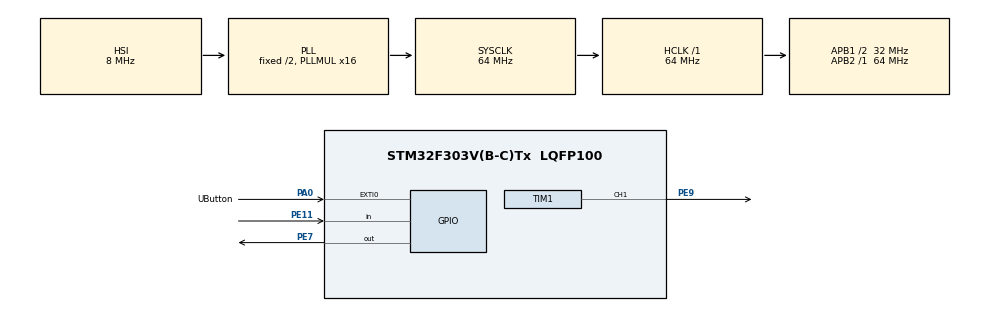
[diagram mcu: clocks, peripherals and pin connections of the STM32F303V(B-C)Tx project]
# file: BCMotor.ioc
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Mcu.Family=STM32F3
Mcu.Name=STM32F303V(B-C)Tx
Mcu.Package=LQFP100
NVIC.EXTI0_IRQn=true\:0\:0\:false\:false\:true\:true\:true
NVIC.PriorityGroup=NVIC_PRIORITYGROUP_0
NVIC.TIM1_CC_IRQn=true\:0\:0\:false\:false\:true\:true\:true
PA0.GPIO_Label=UButton
PA0.Signal=GPXTI0
PE11.Signal=GPIO_Input
PE7.Signal=GPIO_Output
PE9.Signal=S_TIM1_CH1
PF0-OSC_IN.GPIO_Label=OSC_IN
PF0-OSC_IN.Mode=HSE-External-Oscillator
PF0-OSC_IN.Signal=RCC_OSC_IN
PF1-OSC_OUT.Mode=HSE-External-Oscillator
PF1-OSC_OUT.Signal=RCC_OSC_OUT
ProjectManager.HeapSize=0x200
ProjectManager.StackSize=0x400
ProjectManager.TargetToolchain=SW4STM32
RCC.AHBFreq_Value=64000000
RCC.APB1CLKDivider=RCC_HCLK_DIV2
RCC.APB1Freq_Value=32000000
RCC.APB1TimFreq_Value=64000000
RCC.APB2Freq_Value=64000000
RCC.APB2TimFreq_Value=64000000
RCC.CortexFreq_Value=64000000
RCC.HCLKFreq_Value=64000000
RCC.HSE_VALUE=8000000
RCC.HSI_VALUE=8000000
RCC.LSE_VALUE=32768
RCC.PLLMUL=RCC_PLL_MUL16
RCC.SYSCLKFreq_VALUE=64000000
RCC.SYSCLKSourceVirtual=RCC_SYSCLKSOURCE_PLLCLK
RCC.USBFreq_Value=64000000
SH.S_TIM1_CH1.0=TIM1_CH1,PWM Generation1 CH1
TIM1.Channel-PWM\ Generation1\ CH1=TIM_CHANNEL_1
TIM1.Period=100
TIM1.Prescaler=64
TIM1.Pulse-PWM\ Generation1\ CH1=50
VP_TIM1_VS_ClockSourceINT.Mode=Internal
board=STM32F3DISCOVERY

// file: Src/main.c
/* USER CODE BEGIN Header */
/**
  ******************************************************************************
  * @file           : main.c
  * @brief          : Main program body
  ******************************************************************************
  * @attention
  *
  * <h2><center>&copy; Copyright (c) 2019 STMicroelectronics.
  * All rights reserved.</center></h2>
  *
  * This software component is licensed by ST under BSD 3-Clause license,
  * the "License"; You may not use this file except in compliance with the
  * License. You may obtain a copy of the License at:
  *                        opensource.org/licenses/BSD-3-Clause
  *
  ******************************************************************************
  */
/* USER CODE END Header */

#include "main.h"
#include "tim.h"
#include "gpio.h"

void SystemClock_Config(void);
/* USER CODE BEGIN PFP */
volatile int button_is_pressed = 1;
void HAL_GPIO_EXTI_Callback(uint16_t GPIO_Pin)
{
 if( GPIO_Pin == UButton_Pin)
 {
  static uint32_t last_change_tick;
  if( HAL_GetTick() - last_change_tick < 50 )
  {
   return;
  }
  last_change_tick = HAL_GetTick();
  if(button_is_pressed)
  {
   button_is_pressed = 0;
  }else
  {
   button_is_pressed = 1;
  }
 }
}
/* USER CODE END PFP */

int main(void)
{

  /* MCU Configuration--------------------------------------------------------*/

  /* Reset of all peripherals, Initializes the Flash interface and the Systick. */
  HAL_Init();

  /* Configure the system clock */
  SystemClock_Config();

  /* Initialize all configured peripherals */
  MX_GPIO_Init();
  MX_TIM1_Init();
  /* USER CODE BEGIN 2 */
//  HAL_TIM_PWM_Start(&htim1, TIM_CHANNEL_1);
  /* USER CODE END 2 */

  /* Infinite loop */
  /* USER CODE BEGIN WHILE */
  while (1)
  {
//	  __enable_irq();
//	  if(button_is_pressed) {
//		  HAL_GPIO_WritePin(GPIOE, GPIO_PIN_7, GPIO_PIN_SET);
//		  TIM1->CCR1 = 300;
//	  } else {
//		  HAL_GPIO_WritePin(GPIOE, GPIO_PIN_7, GPIO_PIN_RESET);
//		  TIM1->CCR1 = 750;
//	  }
//
//	  __disable_irq();
	  HAL_GPIO_WritePin(GPIOE, GPIO_PIN_7, GPIO_PIN_SET);
//	  HAL_GPIO_WritePin(GPIOE, GPIO_PIN_9, GPIO_PIN_SET);
	  HAL_GPIO_WritePin(GPIOE, GPIO_PIN_11, GPIO_PIN_RESET);
//	     HAL_Delay(100);
//	     HAL_GPIO_WritePin(GPIOE, GPIO_PIN_8, GPIO_PIN_RESET);
//	     HAL_Delay(100);

    /* USER CODE END WHILE */

  }
}

void SystemClock_Config(void)
{
  RCC_OscInitTypeDef RCC_OscInitStruct = {0};
  RCC_ClkInitTypeDef RCC_ClkInitStruct = {0};
  RCC_PeriphCLKInitTypeDef PeriphClkInit = {0};

  /** Initializes the CPU, AHB and APB busses clocks
  */
  RCC_OscInitStruct.OscillatorType = RCC_OSCILLATORTYPE_HSI;
  RCC_OscInitStruct.HSIState = RCC_HSI_ON;
  RCC_OscInitStruct.HSICalibrationValue = RCC_HSICALIBRATION_DEFAULT;
  RCC_OscInitStruct.PLL.PLLState = RCC_PLL_ON;
  RCC_OscInitStruct.PLL.PLLSource = RCC_PLLSOURCE_HSI;
  RCC_OscInitStruct.PLL.PLLMUL = RCC_PLL_MUL16;
  if (HAL_RCC_OscConfig(&RCC_OscInitStruct) != HAL_OK)
  {
    Error_Handler();
  }
  /** Initializes the CPU, AHB and APB busses clocks
  */
  RCC_ClkInitStruct.ClockType = RCC_CLOCKTYPE_HCLK|RCC_CLOCKTYPE_SYSCLK
                              |RCC_CLOCKTYPE_PCLK1|RCC_CLOCKTYPE_PCLK2;
  RCC_ClkInitStruct.SYSCLKSource = RCC_SYSCLKSOURCE_PLLCLK;
  RCC_ClkInitStruct.AHBCLKDivider = RCC_SYSCLK_DIV1;
  RCC_ClkInitStruct.APB1CLKDivider = RCC_HCLK_DIV2;
  RCC_ClkInitStruct.APB2CLKDivider = RCC_HCLK_DIV1;

  if (HAL_RCC_ClockConfig(&RCC_ClkInitStruct, FLASH_LATENCY_2) != HAL_OK)
  {
    Error_Handler();
  }
  PeriphClkInit.PeriphClockSelection = RCC_PERIPHCLK_TIM1;
  PeriphClkInit.Tim1ClockSelection = RCC_TIM1CLK_HCLK;
  if (HAL_RCCEx_PeriphCLKConfig(&PeriphClkInit) != HAL_OK)
  {
    Error_Handler();
  }
}

void Error_Handler(void)
{
}

/************************ (C) COPYRIGHT STMicroelectronics *****END OF FILE****/
